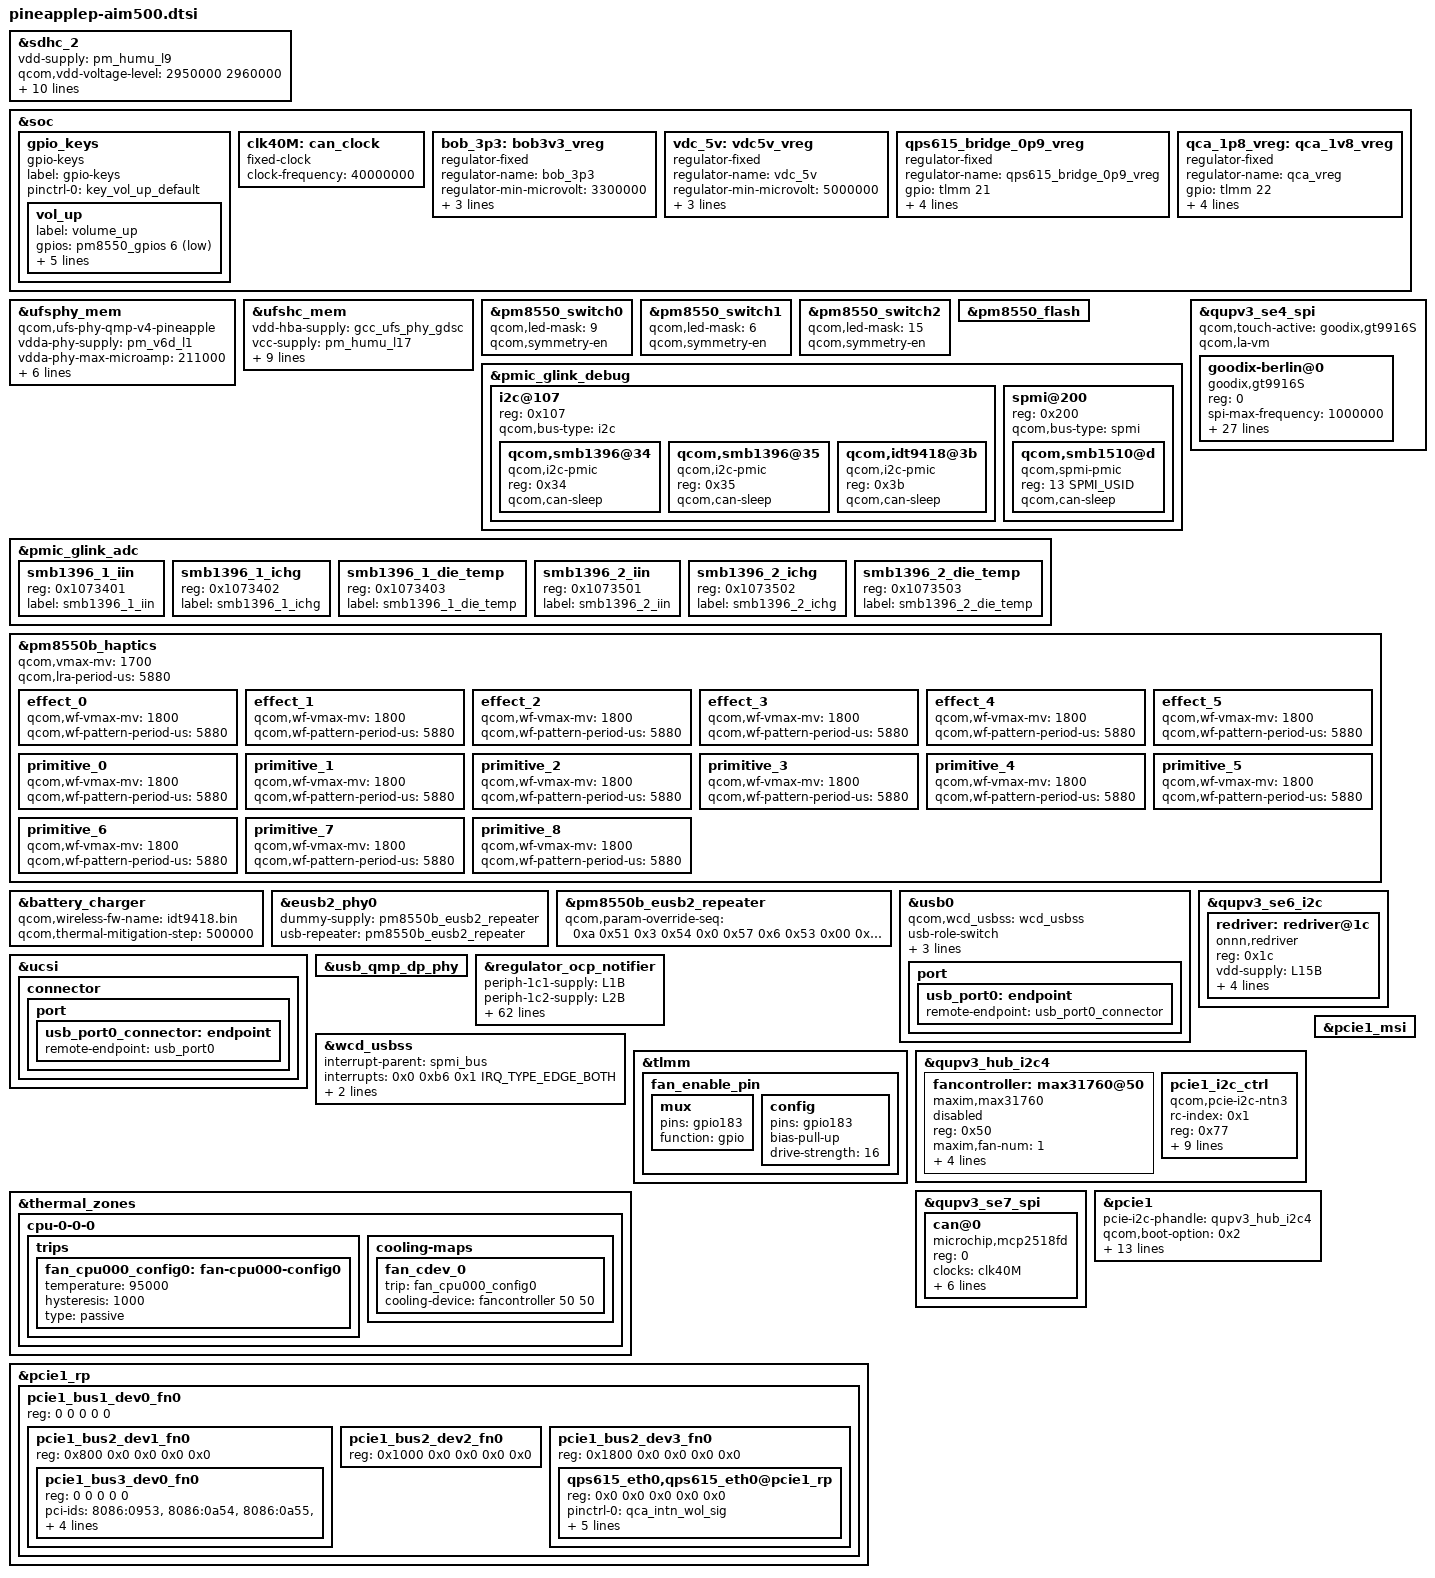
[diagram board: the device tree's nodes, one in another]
#include <dt-bindings/gpio/gpio.h>
#include <dt-bindings/input/input.h>
#include <dt-bindings/clock/qcom,gcc-pineapple.h>
#include "pineapple-pmic-overlay.dtsi"
#include "pineapple-thermal-overlay.dtsi"

&sdhc_2 {
	status = "ok";
	vdd-supply = <&pm_humu_l9>;
	qcom,vdd-voltage-level = <2950000 2960000>;
	qcom,vdd-current-level = <0 800000>;

	vdd-io-supply = <&pm_humu_l8>;
	qcom,vdd-io-voltage-level = <1800000 2960000>;
	qcom,vdd-io-current-level = <0 10000>;

	pinctrl-names = "default", "sleep";
	pinctrl-0 = <&sdc2_on>, <&sd_card_det_default>;
	pinctrl-1 = <&sdc2_off>, <&sd_card_det_default>;

	cd-gpios = <&pm8550_gpios 12 GPIO_ACTIVE_HIGH>;

	resets = <&gcc GCC_SDCC2_BCR>;
	reset-names = "core_reset";

	qcom,iommu-dma = "fastmap";
	qcom,uses_level_shifter;
};

&soc {
	gpio_keys {
		compatible = "gpio-keys";
		label = "gpio-keys";

		pinctrl-names = "default";
		pinctrl-0 = <&key_vol_up_default>;

		vol_up {
			label = "volume_up";
			gpios = <&pm8550_gpios 6 GPIO_ACTIVE_LOW>;
			linux,input-type = <1>;
			linux,code = <KEY_VOLUMEUP>;
			gpio-key,wakeup;
			debounce-interval = <15>;
			linux,can-disable;
		};
	};

	clk40M: can_clock {
		compatible = "fixed-clock";
		#clock-cells = <0>;
		clock-frequency = <40000000>;
	};

	bob_3p3: bob3v3_vreg {
		compatible = "regulator-fixed";
		regulator-name = "bob_3p3";

		regulator-min-microvolt = <3300000>;
		regulator-max-microvolt = <3300000>;
		regulator-always-on;
		vin-supply = <&L15B>;
	};

	vdc_5v: vdc5v_vreg {
		compatible = "regulator-fixed";
		regulator-name = "vdc_5v";

		regulator-min-microvolt = <5000000>;
		regulator-max-microvolt = <5000000>;
		regulator-always-on;
		vin-supply = <&bob_3p3>;
	};

	qps615_bridge_0p9_vreg: qps615_bridge_0p9_vreg {
		compatible = "regulator-fixed";
		regulator-name = "qps615_bridge_0p9_vreg";
		gpio = <&tlmm 21 GPIO_ACTIVE_HIGH>;
		regulator-min-microvolt = <1000000>;
		regulator-max-microvolt = <1000000>;
		enable-active-high;
		regulator-enable-ramp-delay = <4300>;
	};

	qca_1p8_vreg: qca_1v8_vreg {
		compatible = "regulator-fixed";
		regulator-name = "qca_vreg";
		gpio = <&tlmm 22 GPIO_ACTIVE_HIGH>;
		regulator-min-microvolt = <1800000>;
		regulator-max-microvolt = <1800000>;
		enable-active-high;
		regulator-enable-ramp-delay = <80000>;
	};
};

&ufsphy_mem {
	compatible = "qcom,ufs-phy-qmp-v4-pineapple";

	/* VDDA_UFS_CORE */
	vdda-phy-supply = <&pm_v6d_l1>;
	vdda-phy-max-microamp = <211000>;
	/*
	 * Platforms supporting Gear 5 && Rate B require a different
	 * voltage supply. Check the Power Grid document.
	 */
	vdda-phy-min-microvolt = <912000>;

	/* VDDA_UFS_0_1P2 */
	vdda-pll-supply = <&pm_v8_l3>;
	vdda-pll-max-microamp = <18300>;

	/* Phy GDSC for VDD_MX, always on */
	vdd-phy-gdsc-supply = <&gcc_ufs_mem_phy_gdsc>;

	/* Qref power supply, Refer Qref diagram */
	vdda-qref-supply = <&pm_v8_l1>;
	vdda-qref-max-microamp = <64500>;

	status = "ok";
};

&ufshc_mem {
	vdd-hba-supply = <&gcc_ufs_phy_gdsc>;

	vcc-supply = <&pm_humu_l17>;
	vcc-max-microamp = <1300000>;

	vccq-supply = <&pm_v6c_l1>;
	vccq-max-microamp = <1200000>;

	/* VDD_PX10 is voted for the ufs_reset_n */
	qcom,vddp-ref-clk-supply = <&pm_v6c_l3>;
	qcom,vddp-ref-clk-max-microamp = <100>;

	qcom,vccq-parent-supply = <&pm_v6c_s1>;
	qcom,vccq-parent-max-microamp = <210000>;

	reset-gpios = <&tlmm 210 GPIO_ACTIVE_LOW>;
	resets = <&gcc GCC_UFS_PHY_BCR>;
	reset-names = "rst";

	status = "ok";
};

&pm8550_switch0 {
	qcom,led-mask = <9>; /* Channels 1 & 4 */
	qcom,symmetry-en;
};

&pm8550_switch1 {
	qcom,led-mask = <6>; /* Channels 2 & 3 */
	qcom,symmetry-en;
};

&pm8550_switch2 {
	qcom,led-mask = <15>; /* All Channels */
	qcom,symmetry-en;
};

&pm8550_flash {
	status = "ok";
};

&pmic_glink_debug {
	i2c@107 {
		reg = <0x107>; /* I2C instance 7 in ADSP for SE6 */
		#address-cells = <1>;
		#size-cells = <0>;
		qcom,bus-type = "i2c";

		qcom,smb1396@34 {
			compatible = "qcom,i2c-pmic";
			reg = <0x34>;
			qcom,can-sleep;
		};

		qcom,smb1396@35 {
			compatible = "qcom,i2c-pmic";
			reg = <0x35>;
			qcom,can-sleep;
		};

		qcom,idt9418@3b {
			compatible = "qcom,i2c-pmic";
			reg = <0x3b>;
			qcom,can-sleep;
		};
	};

	/* SPMI bridge bus 0 with SMB1510 device */
	spmi@200 {
		reg = <0x200>;
		#address-cells = <2>;
		#size-cells = <0>;
		qcom,bus-type = "spmi";

		qcom,smb1510@d {
			compatible = "qcom,spmi-pmic";
			reg = <13 SPMI_USID>;
			qcom,can-sleep;
		};
	};
};

&pmic_glink_adc {
	status = "ok";

	smb1396_1_iin {
		reg = <0x1073401>;
		label = "smb1396_1_iin";
	};

	smb1396_1_ichg {
		reg = <0x1073402>;
		label = "smb1396_1_ichg";
	};

	smb1396_1_die_temp {
		reg = <0x1073403>;
		label = "smb1396_1_die_temp";
	};

	smb1396_2_iin {
		reg = <0x1073501>;
		label = "smb1396_2_iin";
	};

	smb1396_2_ichg {
		reg = <0x1073502>;
		label = "smb1396_2_ichg";
	};

	smb1396_2_die_temp {
		reg = <0x1073503>;
		label = "smb1396_2_die_temp";
	};
};

&qupv3_se4_spi {
	#address-cells = <1>;
	#size-cells = <0>;
	status = "ok";
	qcom,touch-active = "goodix,gt9916S";
	qcom,la-vm;

	goodix-berlin@0 {
		compatible = "goodix,gt9916S";
		reg = <0>;
		spi-max-frequency = <1000000>;

		goodix,avdd-name = "avdd";
		avdd-supply = <&L14B>;

		interrupt-parent = <&tlmm>;
		interrupts = <162 0x2008>;
		goodix,reset-gpio = <&tlmm 161 0x00>;
		goodix,irq-gpio = <&tlmm 162 0x2008>;
		goodix,irq-flags = <2>;
		goodix,panel-max-x = <1080>;
		goodix,panel-max-y = <2400>;
		goodix,panel-max-w = <255>;
		goodix,panel-max-p = <4096>;
		goodix,firmware-name = "goodix_firmware_spi.bin";
		goodix,config-name = "goodix_cfg_group_spi.bin";

		pinctrl-names = "pmx_ts_active", "pmx_ts_suspend", "pmx_ts_release";
		pinctrl-0 = <&ts_active>;
		pinctrl-1 = <&ts_int_suspend &ts_reset_suspend>;
		pinctrl-2 = <&ts_release>;

		goodix,touch-type = "primary";
		goodix,qts_en;
		qts,trusted-touch-mode = "vm_mode";
		qts,touch-environment = "pvm";
		qts,trusted-touch-type = "primary";
		qts,trusted-touch-spi-irq = <598>;
		qts,trusted-touch-io-bases = <0xa90000>;
		qts,trusted-touch-io-sizes = <0x1000>;
		qts,trusted-touch-vm-gpio-list = <&tlmm 48 0 &tlmm 49 0 &tlmm 50 0
						&tlmm 51 0 &tlmm 161 0 &tlmm 162 0x2008>;
	};
};

&pm8550b_haptics {
	qcom,vmax-mv = <1700>;
	qcom,lra-period-us = <5880>;

	effect_0 {
		/* CLICK */
		qcom,wf-vmax-mv = <1800>;
		qcom,wf-pattern-period-us = <5880>;
	};

	effect_1 {
		/* DOUBLE_CLICK */
		qcom,wf-vmax-mv = <1800>;
		qcom,wf-pattern-period-us = <5880>;
	};

	effect_2 {
		/* TICK */
		qcom,wf-vmax-mv = <1800>;
		qcom,wf-pattern-period-us = <5880>;
	};

	effect_3 {
		/* THUD */
		qcom,wf-vmax-mv = <1800>;
		qcom,wf-pattern-period-us = <5880>;
	};

	effect_4 {
		/* POP */
		qcom,wf-vmax-mv = <1800>;
		qcom,wf-pattern-period-us = <5880>;
	};

	effect_5 {
		/* HEAVY CLICK */
		qcom,wf-vmax-mv = <1800>;
		qcom,wf-pattern-period-us = <5880>;
	};

	primitive_0 {
		/* NOOP */
		qcom,wf-vmax-mv = <1800>;
		qcom,wf-pattern-period-us = <5880>;
	};

	primitive_1 {
		/* CLICK */
		qcom,wf-vmax-mv = <1800>;
		qcom,wf-pattern-period-us = <5880>;
	};

	primitive_2 {
		/* THUD */
		qcom,wf-vmax-mv = <1800>;
		qcom,wf-pattern-period-us = <5880>;
	};

	primitive_3 {
		/* SPIN */
		qcom,wf-vmax-mv = <1800>;
		qcom,wf-pattern-period-us = <5880>;
	};

	primitive_4 {
		/* QUICK_RISE */
		qcom,wf-vmax-mv = <1800>;
		qcom,wf-pattern-period-us = <5880>;
	};

	primitive_5 {
		/* SLOW_RISE */
		qcom,wf-vmax-mv = <1800>;
		qcom,wf-pattern-period-us = <5880>;
	};

	primitive_6 {
		/* QUICK_FALL */
		qcom,wf-vmax-mv = <1800>;
		qcom,wf-pattern-period-us = <5880>;
	};

	primitive_7 {
		/* LIGHT_TICK */
		qcom,wf-vmax-mv = <1800>;
		qcom,wf-pattern-period-us = <5880>;
	};

	primitive_8 {
		/* LOW_TICK */
		qcom,wf-vmax-mv = <1800>;
		qcom,wf-pattern-period-us = <5880>;
	};
};

&battery_charger {
	qcom,wireless-fw-name = "idt9418.bin";
	qcom,thermal-mitigation-step = <500000>;
	#cooling-cells = <2>;
};

&eusb2_phy0 {
	dummy-supply = <&pm8550b_eusb2_repeater>;
	usb-repeater = <&pm8550b_eusb2_repeater>;
};

&pm8550b_eusb2_repeater {
	qcom,param-override-seq =
		/* <value reg_offset> */
		/* Adjust HS trasmit amplitude */
		<0xa 0x51
		/* Squelch detection threshold */
		 0x3 0x54
		/* Tx pre-emphasis tuning */
		 0x0 0x57
		/* HS disconnect threshold */
		 0x6 0x53
		/* slew rate */
		 0x00 0x59>;
};

&usb0 {
	qcom,wcd_usbss = <&wcd_usbss>;
	usb-role-switch;
	port {
		usb_port0: endpoint {
			remote-endpoint = <&usb_port0_connector>;
		};
	};
};

&ucsi {
	connector {
		port {
			usb_port0_connector: endpoint {
				remote-endpoint = <&usb_port0>;
			};
		};
	};
};

&qupv3_se6_i2c {
	status = "ok";

	#address-cells = <1>;
	#size-cells = <0>;
	redriver: redriver@1c {
		compatible = "onnn,redriver";
		reg = <0x1c>;

		vdd-supply = <&L15B>;

		eq = /bits/ 8 <
				/* Parameters for USB */
				0x4 0x6 0x6 0x4
				/* Parameters for DP */
				0x5 0x7 0x7 0x5>;
		flat-gain = /bits/ 8 <
				/* Parameters for USB */
				0x3 0x3 0x3 0x3
				/* Parameters for DP */
				0x0 0x3 0x3 0x0>;
		output-comp = /bits/ 8 <
				/* Parameters for USB */
				0x3 0x3 0x3 0x3
				/* Parameters for DP */
				0x3 0x3 0x3 0x3>;
		loss-match = /bits/ 8 <
				/* Parameters for USB */
				0x1 0x3 0x3 0x1
				/* Parameters for DP */
				0x2 0x2 0x2 0x2>;
	};
};

&usb_qmp_dp_phy {
	pinctrl-names = "unused";
};

&usb0 {
	pinctrl-names = "default";
	pinctrl-0 = <&usb3phy_portselect_gpio>;
	gpios = <&tlmm 29 0>;

	ssusb_redriver = <&redriver>;
};

&regulator_ocp_notifier {
	periph-1c1-supply = <&L1B>;
	periph-1c2-supply = <&L2B>;
	periph-1c5-supply = <&L5B>;
	periph-1c6-supply = <&L6B>;
	periph-1c7-supply = <&L7B>;
	periph-1c8-supply = <&L8B>;
	periph-1c9-supply = <&L9B>;
	periph-1ca-supply = <&L10B>;
	periph-1cb-supply = <&L11B>;
	periph-1cc-supply = <&L12B>;
	periph-1cd-supply = <&L13B>;
	periph-1ce-supply = <&L14B>;
	periph-1cf-supply = <&L15B>;
	periph-1d0-supply = <&L16B>;
	periph-1d1-supply = <&L17B>;
	periph-1e4-supply = <&BOB1>;
	periph-1e6-supply = <&BOB2>;
	periph-29b-supply = <&S1C>;
	periph-29e-supply = <&S2C>;
	periph-2a1-supply = <&S3C>;
	periph-2a4-supply = <&S4C>;
	periph-2a7-supply = <&S5C>;
	periph-2aa-supply = <&S6C>;
	periph-2c1-supply = <&L1C>;
	periph-2c2-supply = <&L2C>;
	periph-2c3-supply = <&L3C>;
	periph-3a1-supply = <&S3D_LEVEL>;
	periph-3a4-supply = <&S4D_LEVEL>;
	periph-3a7-supply = <&S5D_LEVEL>;
	periph-3c1-supply = <&L1D>;
	periph-3c2-supply = <&L2D_LEVEL>;
	periph-3c3-supply = <&L3D>;
	periph-4c2-supply = <&L2E>;
	periph-4c3-supply = <&L3E>;
	periph-69b-supply = <&S1G_LEVEL>;
	periph-6a1-supply = <&S3G>;
	periph-6a4-supply = <&S4G_LEVEL>;
	periph-6a7-supply = <&S5G_LEVEL>;
	periph-6c1-supply = <&L1G>;
	periph-6c2-supply = <&L2G>;
	periph-6c3-supply = <&L3G>;
	periph-89b-supply = <&S1I_LEVEL>;
	periph-8a1-supply = <&S3I_LEVEL>;
	periph-8a4-supply = <&S4I>;
	periph-8a7-supply = <&S5I>;
	periph-8aa-supply = <&S6I_LEVEL>;
	periph-8b0-supply = <&S8I_LEVEL>;
	periph-8c1-supply = <&L1I>;
	periph-8c2-supply = <&L2I>;
	periph-8c3-supply = <&L3I>;
	periph-c40-supply = <&L1M>;
	periph-c41-supply = <&L2M>;
	periph-c42-supply = <&L3M>;
	periph-c43-supply = <&L4M>;
	periph-c44-supply = <&L5M>;
	periph-c45-supply = <&L6M>;
	periph-c46-supply = <&L7M>;
	periph-d40-supply = <&L1N>;
	periph-d41-supply = <&L2N>;
	periph-d42-supply = <&L3N>;
	periph-d43-supply = <&L4N>;
	periph-d44-supply = <&L5N>;
	periph-d45-supply = <&L6N>;
	periph-d46-supply = <&L7N>;
};

&wcd_usbss {
	interrupt-parent = <&spmi_bus>;
	interrupts = <0x0 0xb6 0x1 IRQ_TYPE_EDGE_BOTH>;
	interrupt-names = "usb_wcd";
	nvmem-cells = <&usb_mode>;
	nvmem-cell-names = "usb_mode";
};

&tlmm {
	fan_enable_pin {
		mux {
			pins = "gpio183";
			function = "gpio";
		};

		config {
			pins = "gpio183";
			bias-pull-up;
			drive-strength = <16>;
		};
	};
};

&qupv3_hub_i2c4 {
	status = "ok";
	#address-cells = <1>;
	#size-cells = <0>;

	fancontroller: max31760@50 {
		compatible = "maxim,max31760";
		reg = <0x50>;
		#cooling-cells = <2>;
		maxim,fan-num = <1>;
		maxim,vdd-supply = <&BOB1>;
		maxim,vcca-supply = <&L15B>;
		regulator-name = "maxim,vdd", "maxim,vcca";
		maxim,pwr-en-gpio = <&tlmm 183 GPIO_ACTIVE_LOW>;
		status = "disabled";
	};

	pcie1_i2c_ctrl: pcie1_i2c_ctrl {
		compatible = "qcom,pcie-i2c-ntn3";
		rc-index = <0x1>;
		reg = <0x77>;
		gpio-config-reg = <0x801208>;
		ep-reset-reg = <0x801210>;
		ep-reset-gpio-mask = <0xc>;
		version-reg = <0x800000>;
		dump-regs = <0x801330 0x801350 0x801370>;
		reg_update = <0x82c030 0x1
					0x828000 0x3
					0x82bd00 0x8
					0x82c030 0x2
					0x828000 0x3
					0x82bd00 0x8
					0x82c030 0x8
					0x828000 0x1
					0x82bd00 0x8
					0x82c01c 0x10
					0x82c030 0xf
					0x828000 0xf
					0x82b268 0x2>;
		/*FOM for preset caluclation*/
		switch_reg_update = <0x82c02c 0x00000007
					0x824a10 0x00000001
					0x82c030 0x00000008
					0x828000 0x00000001
					0x82b074 0x00000020
					0x82b2bc 0x00000001>;
	};
};

&thermal_zones {
	cpu-0-0-0 {
		trips {
			fan_cpu000_config0: fan-cpu000-config0 {
				temperature = <95000>;
				hysteresis = <1000>;
				type = "passive";
			};
		};

		cooling-maps {
			fan_cdev_0 {
				trip = <&fan_cpu000_config0>;
				cooling-device = <&fancontroller 50 50>;
			};
		};
	};
};

&qupv3_se7_spi {
	status = "ok";
	can@0 {
		compatible = "microchip,mcp2518fd";
		reg = <0>;
		clocks = <&clk40M>;
		interrupts-extended = <&tlmm 10 IRQ_TYPE_LEVEL_LOW>;
		interrupt-names = "can_irq";
		spi-max-frequency = <10000000>;
		gpio-controller;
		vdd-supply = <&vdc_5v>;
		xceiver-supply = <&vdc_5v>;
		status = "ok";
	};
};

&pcie1_msi {
	status = "ok";
};

&pcie1 {
	pcie-i2c-phandle = <&qupv3_hub_i2c4>;
	qcom,boot-option = <0x2>;
	vreg-3p3-supply = <&qps615_bridge_0p9_vreg>;
	msi-parent = <&pcie1_msi>;
	qcom,phy-sequence = <0x1240 0x03 0x0
			0x0030 0x1d 0x0
			0x0034 0x03 0x0
			0x0078 0x01 0x0
			0x007c 0x00 0x0
			0x0080 0x51 0x0
			0x00ac 0x34 0x0
			0x0208 0x0c 0x0
			0x020c 0x0a 0x0
			0x0218 0x04 0x0
			0x0220 0x16 0x0
			0x0234 0x00 0x0
			0x029c 0x80 0x0
			0x02a0 0x7c 0x0
			0x02b4 0x05 0x0
			0x02e8 0x0a 0x0
			0x030c 0x0d 0x0
			0x0320 0x0b 0x0
			0x0348 0x1c 0x0
			0x0388 0x20 0x0
			0x0394 0x30 0x0
			0x03dc 0x09 0x0
			0x03f4 0x14 0x0
			0x03f8 0xb3 0x0
			0x03fc 0x58 0x0
			0x0400 0x9a 0x0
			0x0404 0x26 0x0
			0x0408 0xb6 0x0
			0x040c 0xee 0x0
			0x0410 0xdb 0x0
			0x0414 0xdb 0x0
			0x0418 0xa0 0x0
			0x041c 0xdf 0x0
			0x0420 0x78 0x0
			0x0424 0x76 0x0
			0x0428 0xff 0x0
			0x0830 0x1d 0x0
			0x0834 0x03 0x0
			0x0878 0x01 0x0
			0x087c 0x00 0x0
			0x0880 0x51 0x0
			0x08ac 0x34 0x0
			0x0a08 0x0c 0x0
			0x0a0c 0x0a 0x0
			0x0a18 0x04 0x0
			0x0a20 0x16 0x0
			0x0a34 0x00 0x0
			0x0a9c 0x80 0x0
			0x0aa0 0x7c 0x0
			0x0ab4 0x05 0x0
			0x0ae8 0x0a 0x0
			0x0b0c 0x0d 0x0
			0x0b20 0x0b 0x0
			0x0b48 0x1c 0x0
			0x0b88 0x20 0x0
			0x0b94 0x30 0x0
			0x0bdc 0x09 0x0
			0x0bf4 0x14 0x0
			0x0bf8 0xb3 0x0
			0x0bfc 0x58 0x0
			0x0c00 0x9a 0x0
			0x0c04 0x26 0x0
			0x0c08 0xb6 0x0
			0x0c0c 0xee 0x0
			0x0c10 0xdb 0x0
			0x0c14 0xdb 0x0
			0x0c18 0xa0 0x0
			0x0c1c 0xdf 0x0
			0x0c20 0x78 0x0
			0x0c24 0x76 0x0
			0x0c28 0xff 0x0
			0x0ea0 0x01 0x0
			0x0eb4 0x00 0x0
			0x0ec4 0x00 0x0
			0x0ec8 0x1f 0x0
			0x0ed4 0x12 0x0
			0x0ed8 0x12 0x0
			0x0edc 0xdb 0x0
			0x0ee0 0x9a 0x0
			0x0ee4 0x38 0x0
			0x0ee8 0xb6 0x0
			0x0eec 0x64 0x0
			0x0ef0 0x1f 0x0
			0x0ef4 0x1f 0x0
			0x0ef8 0x1f 0x0
			0x0efc 0x1f 0x0
			0x0f00 0x1f 0x0
			0x0f04 0x1f 0x0
			0x0f0c 0x1f 0x0
			0x0f14 0x1f 0x0
			0x0f1c 0x1f 0x0
			0x0f28 0x5b 0x0
			0x1000 0x26 0x0
			0x1004 0x03 0x0
			0x1010 0x06 0x0
			0x1014 0x16 0x0
			0x1018 0x36 0x0
			0x101c 0x04 0x0
			0x1020 0x0a 0x0
			0x1024 0x1a 0x0
			0x1028 0x68 0x0
			0x1030 0xab 0x0
			0x1034 0xaa 0x0
			0x1038 0x02 0x0
			0x103c 0x12 0x0
			0x1060 0xf8 0x0
			0x1064 0x01 0x0
			0x1070 0x06 0x0
			0x1074 0x16 0x0
			0x1078 0x36 0x0
			0x107c 0x0a 0x0
			0x1080 0x04 0x0
			0x1084 0x0d 0x0
			0x1088 0x41 0x0
			0x1090 0xab 0x0
			0x1094 0xaa 0x0
			0x1098 0x01 0x0
			0x109c 0x00 0x0
			0x10bc 0x0a 0x0
			0x10c0 0x01 0x0
			0x10cc 0x62 0x0
			0x10d0 0x02 0x0
			0x10d8 0x40 0x0
			0x10dc 0x14 0x0
			0x10e0 0x90 0x0
			0x10e4 0x82 0x0
			0x10f4 0x0f 0x0
			0x1110 0x08 0x0
			0x1120 0x46 0x0
			0x1124 0x04 0x0
			0x1140 0x14 0x0
			0x1164 0x34 0x0
			0x1170 0xa0 0x0
			0x1174 0x06 0x0
			0x1184 0x88 0x0
			0x1188 0x14 0x0
			0x1198 0x0f 0x0
			0x129c 0x87 0x0
			0x12a0 0x05 0x0
			0x12a4 0xa1 0x0
			0x1378 0x2e 0x0
			0x1390 0xcc 0x0
			0x13f8 0x00 0x0
			0x13fc 0x22 0x0
			0x141c 0xc1 0x0
			0x1420 0x40 0x0
			0x1450 0x0f 0x0
			0x1490 0x00 0x0
			0x14a0 0x16 0x0
			0x14f0 0x27 0x0
			0x14f4 0x27 0x0
			0x1508 0x02 0x0
			0x155c 0x2e 0x0
			0x157c 0x03 0x0
			0x1584 0x28 0x0
			0x13dc 0x04 0x0
			0x13e0 0x02 0x0
			0x1418 0xc0 0x0
			0x140c 0x1d 0x0
			0x158c 0x0f 0x0
			0x15ac 0xf2 0x0
			0x15c0 0xf2 0x0
			0x1200 0x00 0x0
			0x1244 0x03 0x0>;

	iommu-map = <0x0 &apps_smmu 0x1480 0x1>,
		<0x100 &apps_smmu 0x1481 0x1>,
		<0x208 &apps_smmu 0x1482 0x1>,
		<0x210 &apps_smmu 0x1483 0x1>,
		<0x218 &apps_smmu 0x1484 0x1>,
		<0x300 &apps_smmu 0x1487 0x1>,
		<0x400 &apps_smmu 0x1488 0x1>,
		<0x500 &apps_smmu 0x148c 0x1>,
		<0x501 &apps_smmu 0x148e 0x1>;
};

&pcie1_rp {
	#address-cells = <5>;
	#size-cells = <0>;

	/* BDF 1.0.0 */
	pcie1_bus1_dev0_fn0: pcie1_bus1_dev0_fn0 {
		reg = <0 0 0 0 0>;
		/* BDF 2.1.0 */
		pcie1_bus2_dev1_fn0: pcie1_bus2_dev1_fn0 {
			reg = <0x800 0x0 0x0 0x0 0x0>;
			pcie1_bus3_dev0_fn0: pcie1_bus3_dev0_fn0 {
				reg = <0 0 0 0 0>;
				pci-ids =
					"8086:0953",
					"8086:0a54",
					"8086:0a55",
					"8086:f1a5",
					"8086:f1a5",
					"1c58:0003",
					"1c58:0023",
					"1c5c:1327",
					"1c5f:0540",
					"144d:a821",
					"144d:a822",
					"144d:a808",
					"1d1d:1f1f",
					"1d1d:2807",
					"1d1d:2601",
					"106b:2001",
					"106b:2003",
					"1179:0115",
					"1179:0116";
			};
		};
		/* BDF 2.2.0 */
		pcie1_bus2_dev2_fn0: pcie1_bus2_dev2_fn0 {
			reg = <0x1000 0x0 0x0 0x0 0x0>;
		};
		/* BDF 2.3.0 */
		pcie1_bus2_dev3_fn0: pcie1_bus2_dev3_fn0 {
			reg = <0x1800 0x0 0x0 0x0 0x0>;
			qps615_eth0,qps615_eth0@pcie1_rp {
				reg = <0x0 0x0 0x0 0x0 0x0>;
				pinctrl-names = "default";
				pinctrl-0 = <&qca_intn_wol_sig>;
				qcom,phy-rst-gpio = <0>;
				qcom,phy-rst-delay-us = <120000>;
				phy-supply = <&qca_1p8_vreg>;
				interrupts-extended = <&tlmm 23 IRQ_TYPE_EDGE_FALLING>;
				interrupt-names = "wol_irq";
				#address-cells = <1>;
				#size-cells = <1>;
			};
		};
	};
};
